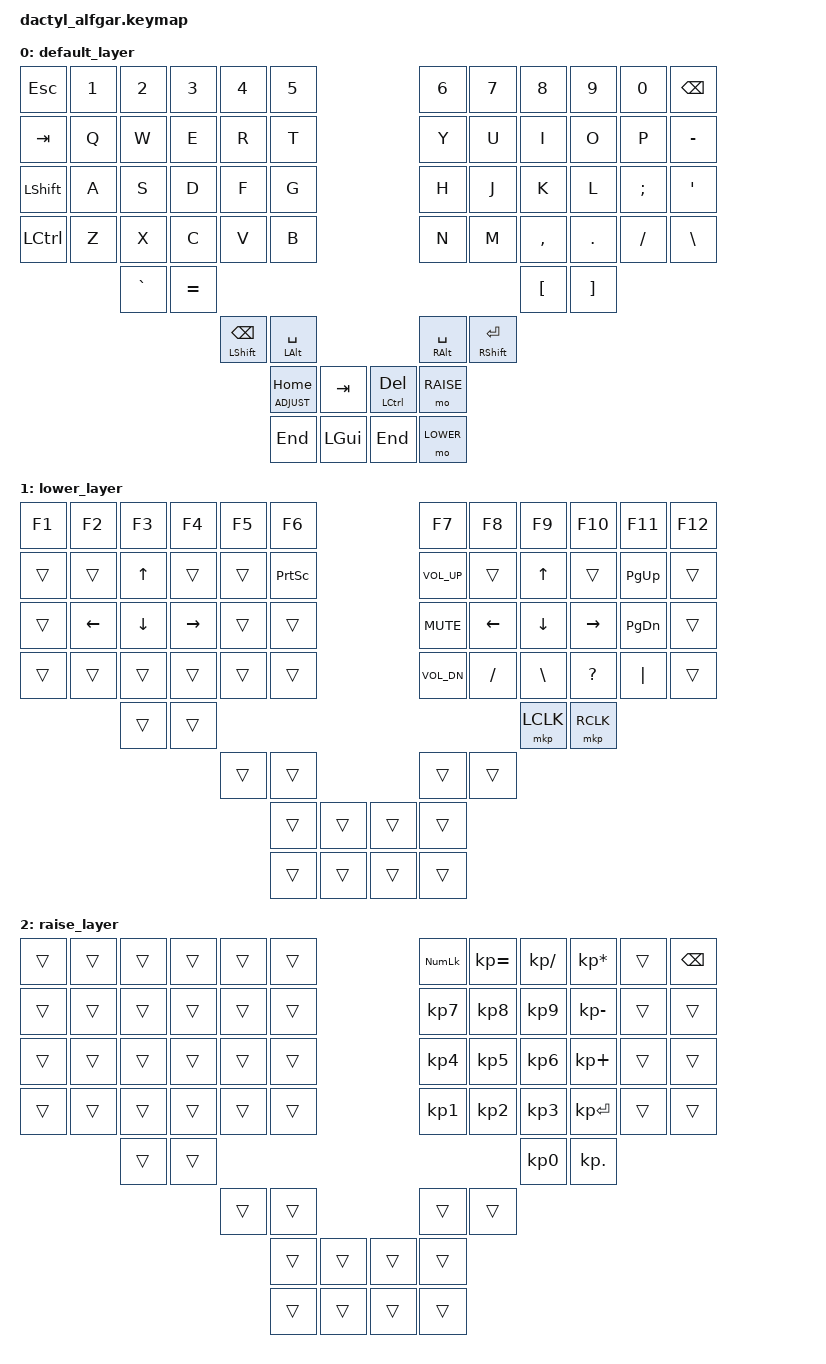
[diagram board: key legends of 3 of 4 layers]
// This file was generated from a template. Edit it to match your keyboard.
// See https://zmk.dev/docs/development/hardware-integration/new-shield for more instructions.

#include <behaviors.dtsi>
#include <dt-bindings/zmk/keys.h>
#include <dt-bindings/zmk/bt.h>
#include <dt-bindings/zmk/outputs.h>
#include <dt-bindings/zmk/mouse.h>

#define DEFAULT 0
#define LOWER 1
#define RAISE 2
#define ADJUST 3

/ {
    // Define a default keymap here.
    // See https://zmk.dev/docs/development/hardware-integration/new-shield#default-keymap.
    keymap {
        compatible = "zmk,keymap";

        default_layer {
            bindings = <
             &kp ESC    &kp N1  &kp N2   &kp N3   &kp N4   &kp N5                                            &kp N6         &kp N7      &kp N8      &kp N9       &kp N0      &kp BSPC
             &kp TAB    &kp Q   &kp W    &kp E    &kp R    &kp T                                             &kp Y          &kp U       &kp I       &kp O           &kp P       &kp MINUS
             &kp LSHIFT &kp A   &kp S    &kp D    &kp F    &kp G                                             &kp H          &kp J       &kp K       &kp L           &kp SEMI    &kp APOS
             &kp LCTRL  &kp Z   &kp X    &kp C    &kp V    &kp B                                             &kp N          &kp M       &kp COMMA   &kp DOT         &kp SLASH   &kp BSLH
                              &kp GRAVE  &kp EQUAL                                                                                      &kp LBKT    &kp RBKT
                                                  &mt LSHFT BSPC &mt LALT SPACE                                &mt RALT SPACE  &mt RSHFT ENTER
                                                           &lt ADJUST HOME  &kp  TAB      &mt LCTRL DEL    &mo RAISE
                                                           &kp END          &kp LGUI      &kp END          &mo LOWER
            >;
        };

        lower_layer {
            bindings = <
             &kp F1 &kp F2 &kp F3 &kp F4 &kp F5 &kp F6                  &kp F7         &kp F8       &kp F9    &kp F10   &kp F11   &kp F12
             &trans &trans &kp UP &trans &trans &kp PSCRN                  &kp C_VOL_UP   &trans       &kp UP    &trans    &kp PG_UP &trans
             &trans &kp LEFT &kp DOWN &kp RIGHT &trans &trans               &kp C_MUTE     &kp LEFT     &kp DOWN  &kp RIGHT &kp PG_DN &trans
             &trans &trans &trans &trans &trans &trans                  &kp C_VOL_DN   &kp FSLH     &kp BSLH  &kp QMARK &kp PIPE  &trans
                           &trans &trans                                               &mkp LCLK    &mkp RCLK
                                         &trans &trans                  &trans &trans
                                                &trans &trans    &trans &trans
                                                &trans &trans    &trans &trans
            >;
        };

        raise_layer  {
            bindings = <
             &trans      &trans        &trans        &trans       &trans        &trans                  &kp KP_NLCK   &kp KP_EQUAL  &kp KP_SLASH  &kp KP_MULTIPLY &trans &kp BSPC
             &trans      &trans        &trans        &trans       &trans        &trans                  &kp KP_N7      &kp KP_N8     &kp KP_N9     &kp KP_MINUS   &trans &trans
             &trans      &trans        &trans        &trans       &trans        &trans                  &kp KP_N4      &kp KP_N5     &kp KP_N6     &kp KP_PLUS    &trans &trans
             &trans      &trans        &trans        &trans       &trans        &trans                  &kp KP_N1      &kp KP_N2     &kp KP_N3     &kp KP_ENTER   &trans &trans
                                       &trans        &trans                                                                          &kp KP_N0     &kp KP_DOT
                                                                  &trans        &trans                  &trans    &trans
                                                                                &trans &trans    &trans &trans
                                                                                &trans &trans    &trans &trans
            >;
        };

        adjust_layer  {
            bindings = <
             &kp F1      &kp F2       &kp F3       &kp F4      &kp F5       &kp F6                  &kp F7   &kp F8  &kp F9  &kp F10 &kp F11 &kp F12
             &none &out OUT_BLE &bt BT_SEL 0 &bt BT_SEL 1 &bt BT_SEL 2  &bt BT_SEL 3                &none    &none   &none   &none   &none    &none
             &none     &out OUT_USB   &none        &none       &none        &bt BT_CLR              &studio_unlock    &none   &none   &none   &none    &none
             &none      &none         &none        &none       &none        &bootloader             &bootloader   &none   &none   &none    &none
                                      &none        &sys_reset                                                            &sys_reset   &none
                                                               &none        &none                   &none    &none
                                                                            &none &none       &none &none
                                                                            &none &none       &none &none
            >;
        };

        extra1 {
            status = "reserved";
        };

        extra2 {
            status = "reserved";
        };
    };
};
